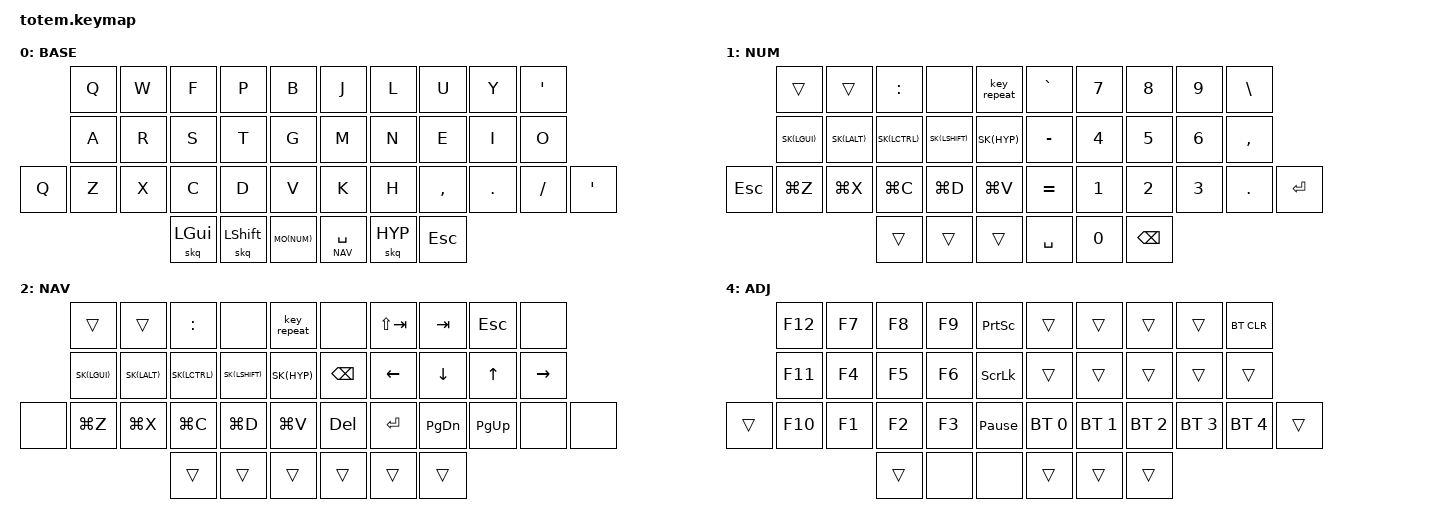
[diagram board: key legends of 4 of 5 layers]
//
//                                                        ▀▀▀▀▀     ▀▀▀▀▀          ▀▀█▀▀
//                                                        ▄▀▀▀▄  ▄  ▄▀▀▀▄  ▄  ▄▀▀▀▄  █  ▄▀▀▀▄
//                                                        █   █  █  █   █  █  █   █  █  █   █
//                                                         ▀▀▀   █   ▀▀▀   █   ▀▀▀   ▀   ▀▀▀
//                                                               █      ▄▄▄█▄▄▄    █   █
//                                                               ▀      █  █  █     █▄█
//                                                             ▀▀▀▀▀    █  █  █      ▀
//                                                                      ▀  ▀  ▀
//
// ▄▄▄▄▄▄▄▄▄▄▄▄▄▄▄▄▄▄▄▄▄▄▄▄▄▄▄▄▄▄▄▄▄▄▄▄▄▄▄▄▄▄▄▄▄▄▄▄▄▄▄▄▄▄▄▄▄▄▄▄▄▄▄▄▄▄▄▄▄▄▄▄▄▄▄▄▄▄▄▄▄▄▄▄▄▄▄▄▄▄▄▄▄▄▄▄▄▄▄▄▄▄▄▄▄▄▄▄▄▄▄▄▄▄▄▄▄▄▄▄▄▄▄▄▄▄▄▄▄▄▄▄▄▄▄▄▄▄▄▄▄▄▄▄▄▄▄▄▄


#include <behaviors.dtsi>
#include <dt-bindings/zmk/keys.h>
#include <dt-bindings/zmk/bt.h>
#include <dt-bindings/zmk/outputs.h>

#define BASE 0
#define NUM  1
#define NAV  2
#define MED  3
#define ADJ  4

#define XXX &none
#define ___ &trans

#define SK(KEY) &nk KEY KEY
#define MO(LAYER) &mo_tap LAYER F24
#define HYP LS(LC(LA(LGUI)))

// Apple "Globe" key
// https://github.com/zmkfirmware/zmk/issues/947
#define GLOBE CAPSLOCK

// Sticky keys timeout after 1.5 seconds
#define STICKY_KEY_TIMEOUT 1500

&sk {
  release-after-ms = <STICKY_KEY_TIMEOUT>;
};

&lt {
  retro-tap;
  tapping_term_ms = <100>;
};

&caps_word {
  continue-list = <UNDERSCORE MINUS BACKSPACE>;
};

&kscan0 {
  debounce-period = <14>;
};

/ {

  combos {
    #include "combos.dtsi"
  };

  macros {
   #include "macros.dtsi"
  };

  behaviors {

    skq: sticky_key_quick_release {
      compatible = "zmk,behavior-sticky-key";
      label = "STICKY_KEY_QUICK_RELEASE";
      #binding-cells = <1>;
      bindings = <&kp>;
      quick-release;
      release-after-ms = <STICKY_KEY_TIMEOUT>;
    };

    // Sticky key on tap, normal key on hold
    // Useful for modifier-clicking without the modifier remaining active
    nk: not_so_sticky_key {
      compatible = "zmk,behavior-hold-tap";
      label = "NOT_SO_STICKY_KEY";
      #binding-cells = <2>;
      tapping_term_ms = <200>;
      flavor = "tap-preferred";
      bindings = <&kp>, <&sk>;
    };

    // A hold-tap that activates without delay (like `&mo`)
    mo_tap: mo_with_tap {
      compatible = "zmk,behavior-hold-tap";
      label = "MO_WITH_TAP";
      #binding-cells = <2>;
      tapping_term_ms = <0>;
      retro-tap;
      flavor = "hold-preferred";
      bindings = <&mo>, <&kp>;
    };

    // A hold-tap that activates without delay (like `&mo`)
    mo_tap: mo_with_tap {
      compatible = "zmk,behavior-hold-tap";
      label = "MO_WITH_TAP";
      #binding-cells = <2>;
      tapping_term_ms = <0>;
      retro-tap;
      flavor = "hold-preferred";
      bindings = <&mo>, <&kp>;
    };

  };

        keymap {
                compatible = "zmk,keymap";
// ▄▄▄▄▄▄▄▄▄▄▄▄▄▄▄▄▄▄▄▄▄▄▄▄▄▄▄▄▄▄▄▄▄▄▄▄▄▄▄▄▄▄▄▄▄▄▄▄▄▄▄▄▄▄▄▄▄▄▄▄▄▄▄▄▄▄▄▄▄▄▄▄▄▄▄▄▄▄▄▄▄▄▄▄▄▄▄▄▄▄▄▄▄▄▄▄▄▄▄▄▄▄▄▄▄▄▄▄▄▄▄▄▄▄▄▄▄▄▄▄▄▄▄▄▄▄▄▄▄▄▄▄▄▄▄▄▄▄▄▄▄▄▄▄▄▄▄▄▄

                base_layer {
// ┏━━━━━━━━━━━━━━━━━━━━━━━━━━━━━━━━━━━━━━━┓
label= "BASE"                              ;
// ┗━━━━━━━━━━━━━━━━━━━━━━━━━━━━━━━━━━━━━━━┛
 bindings = <
//             ┏━━━━━━━━━━━┳━━━━━━━━━━━┳━━━━━━━━━━━┳━━━━━━━━━━━┳━━━━━━━━━━━┓   ┏━━━━━━━━━━━┳━━━━━━━━━━━┳━━━━━━━━━━━┳━━━━━━━━━━━┳━━━━━━━━━━━┓
                &kp Q       &kp W       &kp F       &kp P       &kp B           &kp J       &kp L       &kp U       &kp Y       &kp APOS
//             ┣━━━━━━━━━━━╋━━━━━━━━━━━╋━━━━━━━━━━━╋━━━━━━━━━━━╋━━━━━━━━━━━┫   ┣━━━━━━━━━━━╋━━━━━━━━━━━╋━━━━━━━━━━━╋━━━━━━━━━━━╋━━━━━━━━━━━┫
                &kp A       &kp R       &kp S       &kp T       &kp G           &kp M       &kp N       &kp E       &kp I       &kp O
// ┏━━━━━━━━━━━╋━━━━━━━━━━━╋━━━━━━━━━━━╋━━━━━━━━━━━╋━━━━━━━━━━━╋━━━━━━━━━━━┫   ┣━━━━━━━━━━━╋━━━━━━━━━━━╋━━━━━━━━━━━╋━━━━━━━━━━━╋━━━━━━━━━━━╋━━━━━━━━━━━┓
    &kp Q       &kp Z       &kp X       &kp C       &kp D       &kp V           &kp K       &kp H       &kp COMMA   &kp DOT     &kp FSLH    &kp APOS
// ┗━━━━━━━━━━━┻━━━━━━━━━━━┻━━━━━━━━━━━╋━━━━━━━━━━━╋━━━━━━━━━━━╋━━━━━━━━━━━┫   ┣━━━━━━━━━━━╋━━━━━━━━━━━╋━━━━━━━━━━━╋━━━━━━━━━━━┻━━━━━━━━━━━┻━━━━━━━━━━━┛
                                        &skq LGUI   &skq LSHFT  MO(NUM)        &lt NAV SPACE &skq HYP   &kp ESC
//                                     ┗━━━━━━━━━━━┻━━━━━━━━━━━┻━━━━━━━━━━━┛   ┗━━━━━━━━━━━┻━━━━━━━━━━━┻━━━━━━━━━━━┛
                        >;
                };

// ▄▄▄▄▄▄▄▄▄▄▄▄▄▄▄▄▄▄▄▄▄▄▄▄▄▄▄▄▄▄▄▄▄▄▄▄▄▄▄▄▄▄▄▄▄▄▄▄▄▄▄▄▄▄▄▄▄▄▄▄▄▄▄▄▄▄▄▄▄▄▄▄▄▄▄▄▄▄▄▄▄▄▄▄▄▄▄▄▄▄▄▄▄▄▄▄▄▄▄▄▄▄▄▄▄▄▄▄▄▄▄▄▄▄▄▄▄▄▄▄▄▄▄▄▄▄▄▄▄▄▄▄▄▄▄▄▄▄▄▄▄▄▄▄▄▄▄▄▄


                num_layer {
// ┏━━━━━━━━━━━━━━━━━━━━━━━━━━━━━━━━━━━━━━━┓
label= "NUM"                               ;
// ┗━━━━━━━━━━━━━━━━━━━━━━━━━━━━━━━━━━━━━━━┛
 bindings = <
//             ┏━━━━━━━━━━━┳━━━━━━━━━━━┳━━━━━━━━━━━┳━━━━━━━━━━━┳━━━━━━━━━━━┓   ┏━━━━━━━━━━━┳━━━━━━━━━━━┳━━━━━━━━━━━┳━━━━━━━━━━━┳━━━━━━━━━━━┓
                ___         ___         &kp COLON   XXX         &key_repeat     &kp GRAVE   &kp N7      &kp N8      &kp N9      &kp BSLH
//             ┣━━━━━━━━━━━╋━━━━━━━━━━━╋━━━━━━━━━━━╋━━━━━━━━━━━╋━━━━━━━━━━━┫   ┣━━━━━━━━━━━╋━━━━━━━━━━━╋━━━━━━━━━━━╋━━━━━━━━━━━╋━━━━━━━━━━━┫
                SK(LGUI)    SK(LALT)    SK(LCTRL)   SK(LSHIFT)  SK(HYP)         &kp MINUS   &kp N4      &kp N5      &kp N6      &kp COMMA
// ┏━━━━━━━━━━━╋━━━━━━━━━━━╋━━━━━━━━━━━╋━━━━━━━━━━━╋━━━━━━━━━━━╋━━━━━━━━━━━┫   ┣━━━━━━━━━━━╋━━━━━━━━━━━╋━━━━━━━━━━━╋━━━━━━━━━━━╋━━━━━━━━━━━╋━━━━━━━━━━━┓
    &kp ESC     &kp LG(Z)   &kp LG(X)   &kp LG(C)   &kp LG(D)   &kp LG(V)       &kp EQUAL   &kp N1      &kp N2      &kp N3      &kp DOT     &kp ENTER
// ┗━━━━━━━━━━━┻━━━━━━━━━━━┻━━━━━━━━━━━╋━━━━━━━━━━━╋━━━━━━━━━━━╋━━━━━━━━━━━┫   ┣━━━━━━━━━━━╋━━━━━━━━━━━╋━━━━━━━━━━━╋━━━━━━━━━━━┻━━━━━━━━━━━┻━━━━━━━━━━━┛
                                        ___         ___         ___             &kp SPACE   &kp N0      &kp BSPC
//                                     ┗━━━━━━━━━━━┻━━━━━━━━━━━┻━━━━━━━━━━━┛   ┗━━━━━━━━━━━┻━━━━━━━━━━━┻━━━━━━━━━━━┛
                        >;
                };

// ▄▄▄▄▄▄▄▄▄▄▄▄▄▄▄▄▄▄▄▄▄▄▄▄▄▄▄▄▄▄▄▄▄▄▄▄▄▄▄▄▄▄▄▄▄▄▄▄▄▄▄▄▄▄▄▄▄▄▄▄▄▄▄▄▄▄▄▄▄▄▄▄▄▄▄▄▄▄▄▄▄▄▄▄▄▄▄▄▄▄▄▄▄▄▄▄▄▄▄▄▄▄▄▄▄▄▄▄▄▄▄▄▄▄▄▄▄▄▄▄▄▄▄▄▄▄▄▄▄▄▄▄▄▄▄▄▄▄▄▄▄▄▄▄▄▄▄▄▄


                nav_layer {
// ┏━━━━━━━━━━━━━━━━━━━━━━━━━━━━━━━━━━━━━━━┓
label= "NAV"                               ;
// ┗━━━━━━━━━━━━━━━━━━━━━━━━━━━━━━━━━━━━━━━┛
 bindings = <
//             ┏━━━━━━━━━━━┳━━━━━━━━━━━┳━━━━━━━━━━━┳━━━━━━━━━━━┳━━━━━━━━━━━┓   ┏━━━━━━━━━━━┳━━━━━━━━━━━┳━━━━━━━━━━━┳━━━━━━━━━━━┳━━━━━━━━━━━┓
                ___         ___         &kp COLON   XXX         &key_repeat     XXX         &kp LS(TAB) &kp TAB     &kp ESC     XXX
//             ┣━━━━━━━━━━━╋━━━━━━━━━━━╋━━━━━━━━━━━╋━━━━━━━━━━━╋━━━━━━━━━━━┫   ┣━━━━━━━━━━━╋━━━━━━━━━━━╋━━━━━━━━━━━╋━━━━━━━━━━━╋━━━━━━━━━━━┫
                SK(LGUI)    SK(LALT)    SK(LCTRL)   SK(LSHIFT)  SK(HYP)         &kp BSPC    &kp LEFT    &kp DOWN    &kp UP      &kp RIGHT
// ┏━━━━━━━━━━━╋━━━━━━━━━━━╋━━━━━━━━━━━╋━━━━━━━━━━━╋━━━━━━━━━━━╋━━━━━━━━━━━┫   ┣━━━━━━━━━━━╋━━━━━━━━━━━╋━━━━━━━━━━━╋━━━━━━━━━━━╋━━━━━━━━━━━╋━━━━━━━━━━━┓
    XXX         &kp LG(Z)   &kp LG(X)   &kp LG(C)   &kp LG(D)   &kp LG(V)       &kp DEL     &kp ENTER   &kp PG_DN   &kp PG_UP   XXX         XXX
// ┗━━━━━━━━━━━┻━━━━━━━━━━━┻━━━━━━━━━━━╋━━━━━━━━━━━╋━━━━━━━━━━━╋━━━━━━━━━━━┫   ┣━━━━━━━━━━━╋━━━━━━━━━━━╋━━━━━━━━━━━╋━━━━━━━━━━━┻━━━━━━━━━━━┻━━━━━━━━━━━┛
                                        ___         ___         ___             ___         ___         ___
//                                     ┗━━━━━━━━━━━┻━━━━━━━━━━━┻━━━━━━━━━━━┛   ┗━━━━━━━━━━━┻━━━━━━━━━━━┻━━━━━━━━━━━┛
                        >;
                };

// ▄▄▄▄▄▄▄▄▄▄▄▄▄▄▄▄▄▄▄▄▄▄▄▄▄▄▄▄▄▄▄▄▄▄▄▄▄▄▄▄▄▄▄▄▄▄▄▄▄▄▄▄▄▄▄▄▄▄▄▄▄▄▄▄▄▄▄▄▄▄▄▄▄▄▄▄▄▄▄▄▄▄▄▄▄▄▄▄▄▄▄▄▄▄▄▄▄▄▄▄▄▄▄▄▄▄▄▄▄▄▄▄▄▄▄▄▄▄▄▄▄▄▄▄▄▄▄▄▄▄▄▄▄▄▄▄▄▄▄▄▄▄▄▄▄▄▄▄▄

                media_layer { // 8
// ┏━━━━━━━━━━━━━━━━━━━━━━━━━━━━━━━━━━━━━━━┓
label= "MED"                               ;
// ┗━━━━━━━━━━━━━━━━━━━━━━━━━━━━━━━━━━━━━━━┛
                bindings = <
                        &trans     &trans     &trans      &trans          &trans       &trans           &trans         &trans       &kp C_BRI_UP &kp C_VOL_UP
                        &trans     &trans     &trans      &trans          &trans       &trans           &kp C_PREV     &kp C_VOL_DN &kp C_BRI_DN &kp C_VOL_DN
                        &trans     &trans     &trans      &trans          &trans       &kp C_PLAY_PAUSE &kp C_STOP     &kp C_PREV   &kp C_NEXT   &kp C_MUTE
                                                        &trans          &trans       &kp C_STOP       &kp C_PLAY_PAUSE
                >;
                };

// ▄▄▄▄▄▄▄▄▄▄▄▄▄▄▄▄▄▄▄▄▄▄▄▄▄▄▄▄▄▄▄▄▄▄▄▄▄▄▄▄▄▄▄▄▄▄▄▄▄▄▄▄▄▄▄▄▄▄▄▄▄▄▄▄▄▄▄▄▄▄▄▄▄▄▄▄▄▄▄▄▄▄▄▄▄▄▄▄▄▄▄▄▄▄▄▄▄▄▄▄▄▄▄▄▄▄▄▄▄▄▄▄▄▄▄▄▄▄▄▄▄▄▄▄▄▄▄▄▄▄▄▄▄▄▄▄▄▄▄▄▄▄▄▄▄▄▄▄▄
                adjust_layer { // 9

// ┏━━━━━━━━━━━━━━━━━━━━━━━━━━━━━━━━━━━━━━━┓
label= "ADJ"                               ;
// ┗━━━━━━━━━━━━━━━━━━━━━━━━━━━━━━━━━━━━━━━┛
                bindings = <
                        &kp F12     &kp F7      &kp F8      &kp F9     &kp PSCRN         &trans          &trans         &trans       &trans       &bt BT_CLR
                        &kp F11     &kp F4      &kp F5      &kp F6     &kp SLCK          &trans          &trans         &trans       &trans       &trans
                ___     &kp F10     &kp F1      &kp F2      &kp F3     &kp PAUSE_BREAK   &bt BT_SEL 0    &bt BT_SEL 1   &bt BT_SEL 2 &bt BT_SEL 3 &bt BT_SEL 4  ___
                                                ___         &none      &none             &trans          &trans         ___
                >;
                };
        };
};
